# STM32WL31 register map
File version: 1.0
CPU: CM0+ r0p0, little endian, MPU, no FPU, 4 interrupt priority bits
Registers are 32-bit, read-write, reset 0x0 unless marked. A register's access mark holds for its fields unless they carry their own. Offsets are from the block's base; [hi:lo] are bit positions.

## PWRC
Base 0x48500000
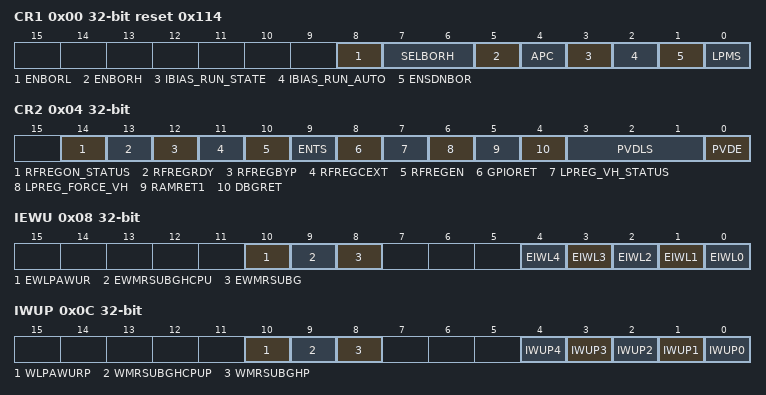
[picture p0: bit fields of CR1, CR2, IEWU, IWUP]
0x00 CR1 reset 0x114
  [8] ENBORL — ENBORL: Enable BORL reset supervising during RUN mode. - 0: No BORL is monitored during RUN mode. - 1: BORL is monitored during RUN mode (a POR reset will happen if VDDIO goes below 1.6V during RUN mode) (default). Note: Enabling this feature prevents blocking the device if VDDIO goes below supported voltages during RUN.
  [7:6] SELBORH — SELBORH[1:0]: BORH selection of Vbor threshold - 11: BORH Level 4(VBOR4): threshold level for above 2.81 V voltage operation. - 10: BORH Level 3 (VBOR3): threshold level for above 2.52 V voltage operation - 01: BORH Level 2 (VBOR2): threshold level for above 2.21 V voltage operation - 00: BORH Level 1 (VBOR1): threshold level for above 2.0V voltage operation.
  [5] ENBORH — ENBORH: enable BORH configuration - 1: BORH is enabled, threshold level depends on SELBOR[1:0] - 0: BORH off (VBOR0): threshold level for above 1.60V voltage operation.
  [4] APC — APC Apply Pull-up and pull-down configuration from CPU - 1: the I/O pull-up and pull-down configurations defined in the PUCRx and PDCRx registers is applied. - 0: the PUCRx and PDCRx are not used to control the I/O pull-up and pull-down configuration of the product I/Os.
  [3] IBIAS_RUN_STATE — IBIAS_RUN_STATE: Enable/Disable IBIAS during RUN mode when automatic mode is disabled. - 0: IBIAS control is disabled (default). - 1: IBIAS control is enabled.
  [2] IBIAS_RUN_AUTO — IBIAS_RUN_AUTO: Enable automatic IBIAS control during RUN/DEEPSTOP mode. - 0: IBIAS control is manual (and controlled by IBIAS_RUN_STATE register) - 1: IBIAS control is automatic (default).
  [1] ENSDNBOR — ENSDNBOR: Enable BOR supply monitoring during shutdown mode. - 1: the PD_ALL_SHUTDOWN signal is not set during SHUTDOWN mode - 0: the PD_ALL_SHUTDOWN signal is set during SHUTDOWN mode.
  [0] LPMS — LPMS Low Power Mode Selection Selection of the low power mode entered when CPU enters DEEP SLEEP mode and BLE is rdy2sleep. - 0: Deep Stop mode (default) - 1: Shutdown mode
0x04 CR2
  [14] RFREGON_STATUS ro — RFREGON_STATUS: RF Regulator On Status - 1: RF Regulator is enabled - 0: RF Regulator is disabled
  [13] RFREGRDY ro — RFDREGRDY: RF Regulator Ready flag - 1: RF Regulator is ready - 0: RF Regulator is not ready
  [12] RFREGBYP — RFREGBYP: RF Regulator Bypass Enable - 1: LDO output connected to VSMPS. - 0: internally generated 1.2V
  [11] RFREGCEXT — RFREGCEXT: RF Regulator External Supply Bypass - 1: External supply bypass capability - 0: Internal supply only
  [10] RFREGEN — RFREGEN: RF Regulator Enable - 1: Enable RF Regulator - 0: Disable RF Regulator (Note: RF Regulator can still be enabled by the RFSUGB or RCC_CR.HSEON)
  [9] ENTS — ENTS: Enable Temperature Sensor - 1: Temperature sensor is enabled - 0: Temperature sensor is disabled
  [8] GPIORET — GPIORET: GPIO retention enable. - 0: Release GPIO retention after deepstop (Should be reset after restore Context) - 1: Enable GPIO Retention during deepstop (Must be set before deepstop)
  [7] LPREG_VH_STATUS ro — status LPREG VH (1.2v) during DEEPSTOP - 1: LPREG=1.2V during DEEPSTOP - 0: LPREG=1V during DEEPSTOP
  [6] LPREG_FORCE_VH — force LPREG=1.2V during DEEPSTOP - 1: Force LPREG=1.2V during DEEPSTOP - 0: No Force (Default) Note LPREG= 1.2v can still apply when LCDEN or COMP.SCALEREN request it
  [5] RAMRET1 — RAMRET1: RAM1 retention during low power mode - 1: RAM1 bank is powered during low power mode - 0: RAM1 bank is disabled during low power mode (by default)
  [4] DBGRET — DBGRET: PA2 and PA3 retention enable after DEEPSTOP - 0: PA2, PA3 don't retain their status exiting from DEEPSTOP (default). - 1: PA2, PA3 retain their status exiting from DEEPSTOP.
  [3:1] PVDLS — PVDLS[2:0] Programmable Voltage Detector Level selection - 000: 2.05 V - Lowest level - 001: 2.20 V - 010: 2.36 V - 011: 2.52 V - 100: 2.64 V - 101: 2.81 V - 110: 2.91 V - Highest level - 111: External input analog voltage (compare internally to VBGP; When external input VBGP then PVDO=1)
  [0] PVDE — PVDE Programmable Voltage Detector Enable When this bit is set the Power Voltage Detector is enabled
0x08 IEWU
  [10] EWLPAWUR — EWLPAWUR: Wakeup Bubble Enable When this bit is set the Bubble wakeup is enabled and a rising edge will trigger a LPAWUR wakeup event - 0: LPAWUR wakeup disabled. - 1: LPAWUR wakeup enabled.
  [9] EWMRSUBGHCPU — EWMRSUBGHCPU Wakeup MRSUBG Host CPU Enable When this bit is set the MRSUBG HOST CPU wakeup is enabled and a rising edge will trigger a MRSUBG Host CPU wakeup event - 0: MRSUBG Host CPU wakeup disabled. - 1: MRSUBG Host CPU wakeup enabled.
  [8] EWMRSUBG — EWMRSUB Wakeup MRSUBG Enable When this bit is set the MRSUBG wakeup is enabled and a rising edge will trigger a MRSUBG wakeup event - 0: MRSUBG wakeup disabled. - 1: MRSUBG wakeup enabled.
  [4] EIWL4 — EIWL4 Enable Internal Wakeup line LCSC When this bit is set the LCSC wakeup is enabled and an edge will trigger a LCSC wakeup event - 0: wakeup disabled. - 1: wakeup enabled.
  [3] EIWL3 — EIWL3 Enable Internal Wakeup line COMP When this bit is set the COMP wakeup is enabled and an edge will trigger a COMP wakeup event - 0: wakeup disabled. - 1: wakeup enabled.
  [2] EIWL2 — EIWL2 Enable Internal WakeUp line LCD When this bit is set the internal wakeup line is enabled and a rising edge will trigger a CPU wakeup event. - 0: wakeup disabled. - 1: wakeup enabled.
  [1] EIWL1 — EIWL1 Enable Internal WakeUp line RTC When this bit is set the internal wakeup line is enabled and a rising edge will trigger a CPU wakeup event. - 0: wakeup disabled. - 1: wakeup enabled.
  [0] EIWL0 — EWL0 Enable Internal WakeUp line LPUART When this bit is set the internal wakeup line is enabled and a rising edge will trigger a CPU wakeup event. - 0: wakeup disabled. - 1: wakeup enabled.
0x0C IWUP
  [10] WLPAWURP — WLPAWURP: Wakeup polarity for wakeup LPAWUR event. - 0: Detection of wakeup event on rising edge (default). - 1: Detection of wakeup event on falling edge.
  [9] WMRSUBGHCPUP — WMRSUBGHCPUP: Wakeup polarity for internal wakeup MRSUBG Host CPU event - 0: Detection of wakeup event on rising edge (default). - 1: Detection of wakeup event on falling edge.
  [8] WMRSUBGHP — WMRSUBGHP: Wakeup polarity for internal wakeup MRSUBG event - 0: Detection of wakeup event on rising edge (default). - 1: Detection of wakeup event on falling edge.
  [4] IWUP4 — IWUP4: Wakeup polarity for internal wakeup line 4 event (LCSC). - 0: Detection of wakeup event on rising edge (default). - 1: Detection of wakeup event on falling edge.
  [3] IWUP3 — IWUP3: Wakeup polarity for internal wakeup line 3 event (COMP). - 0: Detection of wakeup event on rising edge (default). - 1: Detection of wakeup event on falling edge.
  [2] IWUP2 — IWUP2: Wakeup polarity for internal wakeup line 2 event (LCD). - 0: Detection of wakeup event on rising edge (default). - 1: Detection of wakeup event on falling edge.
  [1] IWUP1 — IWUP1: Wakeup polarity for internal wakeup line 1 event (RTC). - 0: Detection of wakeup event on rising edge (default). - 1: Detection of wakeup event on falling edge.
  [0] IWUP0 — IWUP0: Wakeup polarity for internal wakeup line 0 event (LPUART). - 0: Detection of wakeup event on rising edge (default). - 1: Detection of wakeup event on falling edge.
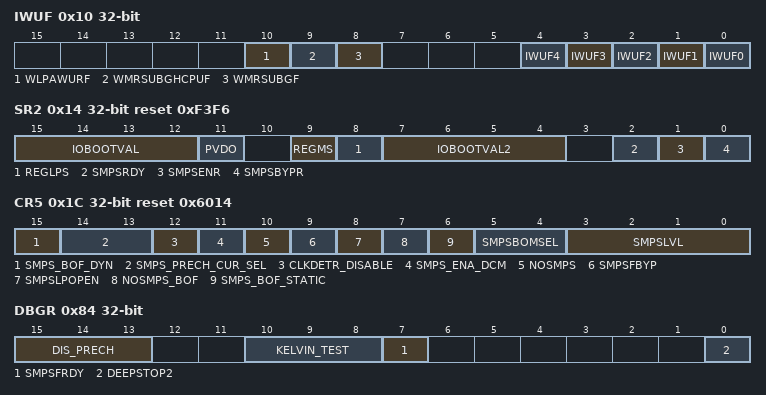
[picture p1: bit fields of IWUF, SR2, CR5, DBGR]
0x10 IWUF
  [10] WLPAWURF — WLPAWURF Wakeup LPAWUR Flag (cf. user manual) This bit is set by hardware when a LPAWUR wakeup is detected It is cleared by a reset pad or by software writing 1 in this bit field. - 0: No LPAWUR wakeup detected - 1: LPAWUR wakeup detected writting 1 in this bit, clears the interrupt
  [9] WMRSUBGHCPUF — WMRSUBGHCPUF Wakeup MRSUBG HOST CPU Flag (cf. user manual) This bit is set by hardware when a MRSUBG HOST CPU wakeup is detected It is cleared by a reset pad or by software writing 1 in this bit field. - 0: No MRSUBG Host CPU wakeup detected - 1: MRSUBG Host CPU wakeup detected writting 1 in this bit, clears the interrupt
  [8] WMRSUBGF — WMRSUBGF Wakeup MRSUBG Flag This bit is set by hardware when a MRSUBG wakeup is detected It is cleared by a reset pad or by software writing 1 in this bit field. - 0: No MRSUBG Wakeup detected - 1: MRSUBG Wakeup detected writting 1 in this bit, clears the interrupt
  [4] IWUF4 — IWUF4: Internal wakeup flag (LCSC). - 0: no wakeup from LCSC occurred since last clear. - 1: a wakeup from LCSC occurred since last clear. Cleared by writing 1 in this bit.
  [3] IWUF3 — IWUF3: Internal wakeup flag (COMP). - 0: no wakeup from COMP occurred since last clear. - 1: a wakeup from COMP occurred since last clear. Cleared by writing 1 in this bit.
  [2] IWUF2 — IWUF2: Internal wakeup flag (LCD). - 0: no wakeup from LCD occurred since last clear. - 1: a wakeup from LCD occurred since last clear. Cleared by writing 1 in this bit.
  [1] IWUF1 — IWUF1: Internal wakeup flag (RTC). - 0: no wakeup from RTC occurred since last clear. - 1: a wakeup from RTC occurred
  [0] IWUF0 — IWUF0: Internal wakeup flag (LPUART). - 0: no wakeup from LPUART occurred since last clear. - 1: a wakeup from LPUART occurred since last clear. Cleared by writing 1 in this bit.
0x14 SR2 ro reset 0xF3F6
  [15:12] IOBOOTVAL — Bit3: PA11 input value on VDD33 latched at POR Bit2: PA10 input value on VDD33 latched at POR Bit1: PA9 input value on VDD33 latched at POR Bit0: PA8 input value on VDD33 latched at POR
  [11] PVDO — PVDO: Power Voltage Detector Output When the Power Voltage Detector is enabled (CR2.PVDE) this bit is set when the system supply (VDDIO) is lower than the selected PVD threshold (CR2.PVDLS)
  [9] REGMS — REGMS: Main regulator ready status. - 0: The Main regulator is not ready. - 1: The Main regulator is ready.
  [8] REGLPS — REGLPS: Regulator Low Power Started This bit provides the information whether low power regulator is ready. - 0: LP regulator is not ready. - 1: LP regulator is ready.
  [7:4] IOBOOTVAL2 — Bit3: PB15 input value on VDD33 latched at POR Bit2: PB14 input value on VDD33 latched at POR Bit1: PB13 input value on VDD33 latched at POR Bit0: PB12 input value on VDD33 latched at POR
  [2] SMPSRDY — SMPSRDY: SMPS Ready Status This bit provides the information whether SMPS is ready. - 0: SMPS regulator is not ready - 1: SMPS regulator is ready.
  [1] SMPSENR — SMPSENR: SMPS Enable Control Replica This bit mirrors the actual ENABLE_3V3 control signal driven to the SMPS regulator, dependant on the real working state.
  [0] SMPSBYPR — SMPSBYPR: SMPS Force Bypass Control Replica This bit mirrors the actual BYPASS_3V3 control signal driven to the SMPS regulator, dependant on the real working state.
0x1C CR5 reset 0x6014
  [15] SMPS_BOF_DYN — SMPS_BOF_DYN: SMPS Bypass on the Fly dynamic - 0 : disabled (by default) - 1 : SMPS Bypass on the fly dynamic is enabled (EN_LDO=1)
  [14:13] SMPS_PRECH_CUR_SEL — SMPS_PRECH_CUR_SEL[1:0] Selection for SMPS PRECHARGE limit current - 00: 2.5mA - 01: 5mA - 10: 10mA - 11: 20mA (default)
  [12] CLKDETR_DISABLE — CLKDETR_DISABLE: disable SMPS clock detection The SMPS clock detection enables an automatic SMPS bypass switching in case of unwanted loss of SMPS clock. - 0 : SMPS clock detection enabled (default) - 1 : SMPS clock detection disabled
  [11] SMPS_ENA_DCM — SMPS_ENA_DCM: enable discontinuous conduction mode - 0 : disable (Default) - 1 : enable
  [10] NOSMPS — NOSMPS: No SMPS Mode When this bit is set, the SMPS regulator will be disabled. Note that this configuration should be used only when SMPS_FB pad is directly connected to VBATT or Vext, without L/C BOM. - 0 : No effect, SMPS is enabled. (Default) - 1 : SMPS is disabled;
  [9] SMPSFBYP — SMPSFB Force SMPS Regulator in bypass mode When this bit is set, the SMPS regulator will be forced to operate in precharge mode. the actual state of SMPS can be observed thanks to the replica SR2.SMPSBYPR. - 0 : no effect (by default) - 1 : SMPS is disabled and bypassed (ENABLE_3V3=0 and PRECHARGE_3V3=1)
  [8] SMPSLPOPEN — SMPSLPOPEN: In Low Power mode SMPS is in OPEN mode (instead of PRECHARGE mode). When this bit is set, when the chip is in Low power mode the SMPS regulator will be disabled (HZ) Documentation needed. - 0 : in Low Power mode, SMPS is in PRECHARGE, output is connected to VDDIO. (default) - 1 : in Low Power mode, SMPS is disabled, output is floating
  [7] NOSMPS_BOF — NOSMPS_BOF: No SMPS Mode to be used in accordance to SMPS_BOF_STATIC =1 When this bit is set, the SMPS regulator will be disabled. Note that this configuration should be used only SMPS_BOF_STATIC=1. - 0 : No effect, SMPS is enabled. (default) - 1 : SMPS is disabled;
  [6] SMPS_BOF_STATIC — SMPS_BOF_STATIC: SMPS Bypass on the Fly static - 0 : disabled (by default) - 1 : SMPS Bypass on the fly static is enabled (EN_SW=1)
  [5:4] SMPSBOMSEL — SMPSBOMSEL: SMPS BOM Selection: - 00: BOM1 - 01: BOM2 (default) - 10: BOM3 - 11: n/a
  [3:0] SMPSLVL — SMPSLVL[3:0] SMPS Output Level Voltage Selection Select the SMPS output voltage with a granularity of 50mV. Default = '0100' (1.4V) Vout = 1.2 + 0.05*SMPSOUT (V)
0x20 PUCRA reset 0xFFF7
  [15:0] PUA — PUA[x] : Pull Up Port A Pull up activation on port A[i] pad when APC bit of PWRC CR1 is set - 1: Pull-Up activated on port A[i] when APC bit of PWRC CR1 bit is set and PWR_PDCRA[x] is reset - 0: Pull-Up not activated on port A[i]
0x24 PDCRA reset 0x8
  [15:0] PDA — PDA[x]: Pull Down Port A Pull Down activation on port A[i] pad when APC bit of PWRC CR1 is set - 1: Pull-Down activated on Port A[i] when APC bit of PWRC CR1 bit is set - 0: Pull-Down not activated on Port A[i]
0x28 PUCRB reset 0xFFFF
  [15:0] PUB — PUB[x] : Pull Up Port B Pull up activation on port B[i] pad when APC bit of PWRC CR1 is set - 1: Pull-Up activated on port B[i] when APC bit of PWRC CR1 bit is set and PWR_PDCRB[x] is reset - 0: Pull-Up not activated on port B[i]
0x2C PDCRB
  [15:0] PDB — PDB[x]: Pull Down Port B Pull Down activation on port B[i] pad when APC bit of PWRC CR1 is set - 1: Pull-Down activated on Port B[i] when APC bit of PWRC CR1 bit is set - 0: Pull-Down not activated on Port B[i]
0x30 EWUA
  [15:0] EWUA — EWUA[x] Enable WakeUp line PA[x] When this bit is set the PA[x] wakeup line is enabled and a rising or falling edge on wakeup line PA[x] will trigger a CPU wakeup event depending on CR7.WUPA[x] bit.
0x34 WUPA
  [15:0] WUPA — WUPA[x] Wake-up Line PA[x] Polarity This bit defines the polarity used for event detection on external wake-up line PA[x] - 0: Detection on high level (rising edge) - 1: Detection on low level (falling edge)
0x38 WUFA
  [15:0] WUFA — WUFA[x] WakeUp Flag PA[x] This bit is set when a wakeup is detected on wakeup line PA[x]. It is cleared by a reset pad or by writing 1 in this bit field. Writing 1 this bit, clears the interrupt:
0x40 EWUB
  [15:0] EWUB — EWUB[x] Enable WakeUp line PB[x] When this bit is set the PB[x] wakeup line is enabled and a rising or falling edge on wakeup line PB[x] will trigger a CPU wakeup event depending on CR9.WUPB[x] bit.
0x44 WUPB
  [15:0] WUPB — WUPB[x] Wake-up Line PB[x] Polarity This bit defines the polarity used for event detection on external wake-up line PB[x] - 0: Detection on high level (rising edge) - 1: Detection on low level (falling edge)
0x48 WUFB
  [15:0] WUFB — WUFB[x] WakeUp Flag PB[x] This bit is set when a wakeup is detected on wakeup line PB[x]. It is cleared by a reset pad or by writing 1 in this bit field. Writing 1 this bit, clears the interrupt:
0x4C SDWN_WUEN
  [0] WUEN — WUEN PB0 I/O WakeUp from shutdown Enable When this bit is set the PB0 wakeup from shutdown is enabled so that a rising or falling edge on PB0 (depending on SDWN_WUPOL..WUPOL bit) will trigger a CPU wakeup. It is cleared by a PORESETn. - 0: PB0 wakeup from shutdown disabled - 1: PB0 wakeup from shutdown enabled
0x50 SDWN_WUPOL
  [0] WUPOL — WUPOL PB0 I/O WakeUp from shutdown Polarity This bit defines the polarity used for wakeup from shutdown detection on PB0 pin. It is cleared by a PORESETn. - 0: Detection on high level (rising edge) - 1: Detection on low level (falling edge)
0x54 SDWN_WUF
  [0] WUF — WUF PB0 I/O WakeUp from shutdown Flag This bit is set when a wakeup from shutdown is detected on PB0 pin. It is cleared by a PORESETn or by writing 0 in this bit field. - 0: Shutdown wakeup from PB0 not occurred - 1: Shutdown wakeup from PB0 occurred
0x58 BOF_TUNE reset 0x4
  [3:0] BOF_TUNE — BOF_TUNE: selection of the Bypass on the Fly LDO output voltage. - 0: 1.2V - 1: 1.2V - 2: 1.2V - 3: 1.3V - 4: 1.4V (Default) - 5: 1.5V - 6: 1.6V - 7: 1.7V - 8: 1.8V - 9: 1.9V - 10: 2V - 11: 2.1V - 12: 2.2V - 13: 2.3V - 14: 2.4V - 15: 2.4V
0x84 DBGR
  [15:13] DIS_PRECH — DIS_PRECH[2:0]: disable precharge during deepstop (debug) allowed combination are: - 111: precharge and SMPS monitoring are disabled (whatever CR5.SMPSLPOPEN) - 101: precharge are activated only at deepstop exit (to be used only with CR5.SMPSLPOPEN=1) else: No effect (default 0x0)
  [10:8] KELVIN_TEST — KELVIN_TEST[2:0]: Enable TEST mode Kelvin for LDO_RF (Write protected by IFR3 key) - 000: 0mA (open) (default 0x0) - 001 for 1mA - 010 for 3mA - 011 for 5mA - 100 for 8mA - 101 for 10mA else: 0mA (open) for other combinations.
  [7] SMPSFRDY — SMPSFB Force ready check When this bit is set, the SMPS regulator will be forced to operate in precharge mode. the actual state of SMPS can be observed thanks to the replica SR2.SMPSBYPR. - 0 : no effect (by default) - 1 : SMPS is disabled and bypassed (ENABLE_3V3=0 and PRECHARGE_3V3=1)
  [0] DEEPSTOP2 — DEEPSTOP2 low power saving mode emulation enable this bit enable an emulated debug DEEPSTOP low power mode. If emulation is enabled, entering in DEEPSTOP mode, the v12i power domain still enters power saving mode, but its clock and power are maintained.
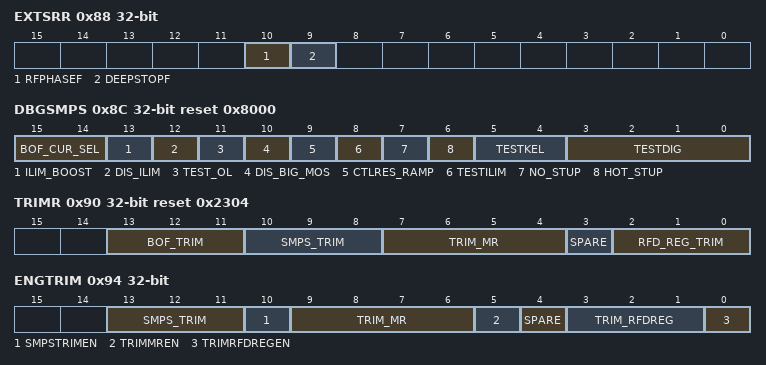
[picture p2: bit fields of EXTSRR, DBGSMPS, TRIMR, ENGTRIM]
0x88 EXTSRR
  [10] RFPHASEF — RFPHASEF RFPHASE Flag This bit is set by hardware after a S3LP wake-up event (S3LP activation); it is cleared either by software, writing '1' in this bit field, or by hardware when Ready2Sleep signal is asserted by the Radio IP. - 0: RF IP does not require attention - 1: RF IP awake and requesting system attention
  [9] DEEPSTOPF — DEEPSTOPF System DeepStop Flag This bit is set by hardware and cleared only by a POR reset or by writing '1' in this bit field - 0: System has not been in DEEPSTOP mode - 1: System has been in DEEPSTOP mode
0x8C DBGSMPS reset 0x8000
  [15:14] BOF_CUR_SEL — BOF_CUR_SEL Bypass On the Fly current limitation - 00 : 20mA - 01 : 40mA - 10 : 60mA (default) - 11 : no limit
  [13] ILIM_BOOST — ILIM_BOOST_3V3 SMPS current limitation Boost - 0: Max current = 110mA (Default) - 1: Max current = 130mA
  [12] DIS_ILIM — DIS_ILIM_3V3 SMPS control signal
  [11] TEST_OL — TEST_OL_3V3 SMPS control signal
  [10] DIS_BIG_MOS — DIS_BIG_MOS_3V3 SMPS control signal
  [9] CTLRES_RAMP — CTLRES_RAM_3V3 SMPS control signal
  [8] TESTILIM — TESTILIM: SMPS TEST_ILIM_3V3 SMPS control signal
  [7] NO_STUP — NO_STUP_3V3 SMPS control signal
  [6] HOT_STUP — HOT_STUP_3V3 SMPS control signal
  [5:4] TESTKEL — TESTKEL: SMPS TEST_KEL_3V3[1:0] SMPS control signal
  [3:0] TESTDIG — TESTDIG: SMPS TEST_DIG_3V3[3:0] SMPS control signal
0x90 TRIMR ro reset 0x2304
  [13:11] BOF_TRIM — BOF_TRIM[2:0]: Bypass On the Fly Output Voltage Trimming By default, this value is taken from the engi bytes; and saved on V12o domain when OBL done. if associated ENGTRIM is enabled the SMPS output voltage can be controlled by the dedicated ENGTRIM register. Default= '100'.
  [10:8] SMPS_TRIM — SMPS_TRIM[2:0]: SMPS Output Voltage Trimming By default, this value is taken from the engi bytes; and saved on V12o domain when OBL done. if associated ENGTRIM is enabled the SMPS output voltage can be controlled by the dedicated ENGTRIM register. Default= '011'.
  [7:4] TRIM_MR — TRIM_MR[3:0]: Main Regulator Voltage Trimming By default, this value is taken from the engi bytes; and saved on V12o domain when OBL done. if associated ENGTRIM.TRIMMREN is enabled the Main Regulator Voltage can be controlled by the dedicated ENGTRIM.TRIM_MR register. Default= '0000'.
  [3] SPARE
  [2:0] RFD_REG_TRIM — RFD_REG_TRIM[2:0]: RF LDO Trimming By default, this value is taken from the engi bytes; and saved on V12o domain when OBL done. if associated ENGTRIM is enabled the RF LDO trimming can be controlled by the dedicated ENGTRIM register. Default= '100'.
0x94 ENGTRIM
  [13:11] SMPS_TRIM — SMPS_TRIM: SMPS Output Voltage Trimming By default, this value is not applied, but taken from the engi bytes; if ENGTRIM.SMPSTRIMEN=1, the SMPS output voltage can be controlled by this register.
  [10] SMPSTRIMEN — SMPSTRIMEN: trimming SMPS enabled - 1: trimming bit applied from ENGTRIM register - 0: trimming bit applied from OBL (can be read on TRIMR register)
  [9:6] TRIM_MR — TRIM_MR: Main Regulator Output Voltage Trimming By default, this value is not applied, but taken from the engi bytes; if ENGTRIM.TRIMMREN=1, the startup current can be controlled by this register.
  [5] TRIMMREN — TRIMMREN: trimming MR enabled - 1: trimming bit applied from ENGTRIM register - 0: trimming bit applied from OBL (can be read on TRIMR register)
  [4] SPARE
  [3:1] TRIM_RFDREG — TRIM_RFDREG: RF Regulator Trimming By default, this value is not applied, but taken from the engi bytes; if ENGTRIM.TRIMRFDREGEN=1, the startup current can be controlled by this register.
  [0] TRIMRFDREGEN — TRIMRFDREGEN: trimming RFREG enabled - 1: trimming bit applied from ENGTRIM register - 0: trimming bit applied from OBL (can be read on TRIMR register)
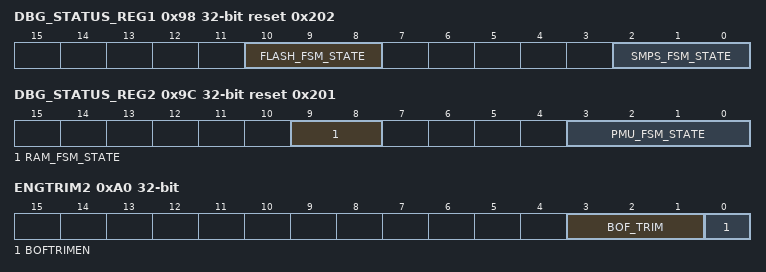
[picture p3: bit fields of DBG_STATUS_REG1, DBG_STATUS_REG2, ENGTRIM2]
0x98 DBG_STATUS_REG1 ro reset 0x202
  [10:8] FLASH_FSM_STATE — FLASH_FSM_STATE[2:0]: Indicates the current state of the FLASH FSM inside the PWRC: - 000: STATE1: FLASH POR - 001: STATE2: FLASH PWRUP - 010: STATE3: FLASH READY - 101: STATE4: FLASH SWITCH OFF - 110: STATE5: FLASH PWR DOWN
  [2:0] SMPS_FSM_STATE — SMPS_FSM_STATE[2:0]: Indicates the current state of the SMPS FSM inside the PWRC.: - 000: STARTUP - 001: SMPS_REQ - 010: SMPS_RUN - 011: STOP - 100: NOSMPS - 101: PRECHARGE - 110: NOSMPS_BOF
0x9C DBG_STATUS_REG2 ro reset 0x201
  [9:8] RAM_FSM_STATE — RAM_FSM_STATE[1:0]: Indicates the current state of the RAM FSM inside the PWRC: - 00: POR - 01: POWER UP - 10: READY - 11: OFF
  [3:0] PMU_FSM_STATE — PMU_FSM_STATE[3:0]: Indicates the current state of the PMU FSM inside the PWRC. - 0000: POR - 0001: RUN - 0010: DS ENTRY - 0011: WAIT1 - 0100: WAIT2 - 0101: WAIT - 0110: WAIT3 - 0111: WAIT4 - 1000: ISOLATION - 1001: DEEPSTOP - 1010: SHUTDOWN - 1011: DEEPSTOP EXIT
0xA0 ENGTRIM2
  [3:1] BOF_TRIM — SMPS_TRIM: SMPS Output Voltage Trimming By default, this value is not applied, but taken from the engi bytes; if ENGTRIM.BOFTRIMEN=1, the SMPS output voltage can be controlled by this register.
  [0] BOFTRIMEN — BOFTRIMEN: trimming BOF enabled - 1: trimming bit applied from ENGTRIM2 register - 0: trimming bit applied from OBL (can be read on TRIMR register)
